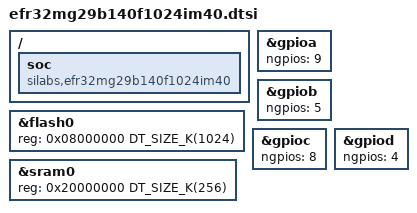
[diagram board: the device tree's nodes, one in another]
/*
 * Copyright (c) 2025 Silicon Laboratories Inc.
 *
 * SPDX-License-Identifier: Apache-2.0
 */

#include <mem.h>
#include <silabs/xg29/efr32mg29.dtsi>

/ {
	soc {
		compatible = "silabs,efr32mg29b140f1024im40", "silabs,efr32mg29", "silabs,xg29",
			     "silabs,efr32", "simple-bus";
	};
};

&flash0 {
	reg = <0x08000000 DT_SIZE_K(1024)>;
};

&gpioa {
	ngpios = <9>;
};

&gpiob {
	ngpios = <5>;
};

&gpioc {
	ngpios = <8>;
};

&gpiod {
	ngpios = <4>;
};

&sram0 {
	reg = <0x20000000 DT_SIZE_K(256)>;
};
